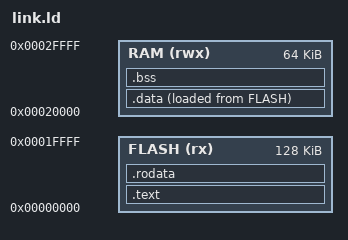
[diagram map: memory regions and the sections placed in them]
MEMORY {
  FLASH (rx)  : ORIGIN = 0x00000000, LENGTH = 128K
  RAM   (rwx) : ORIGIN = 0x00020000, LENGTH = 64K
}
SECTIONS {
  .text : { *(.text.start) *(.text*) } > FLASH
  .rodata : { *(.rodata*) } > FLASH
  .data : { *(.data*) } > RAM AT > FLASH
  .bss  : { *(.bss*) *(COMMON) } > RAM
  _stack_top = ORIGIN(RAM) + LENGTH(RAM);
}
